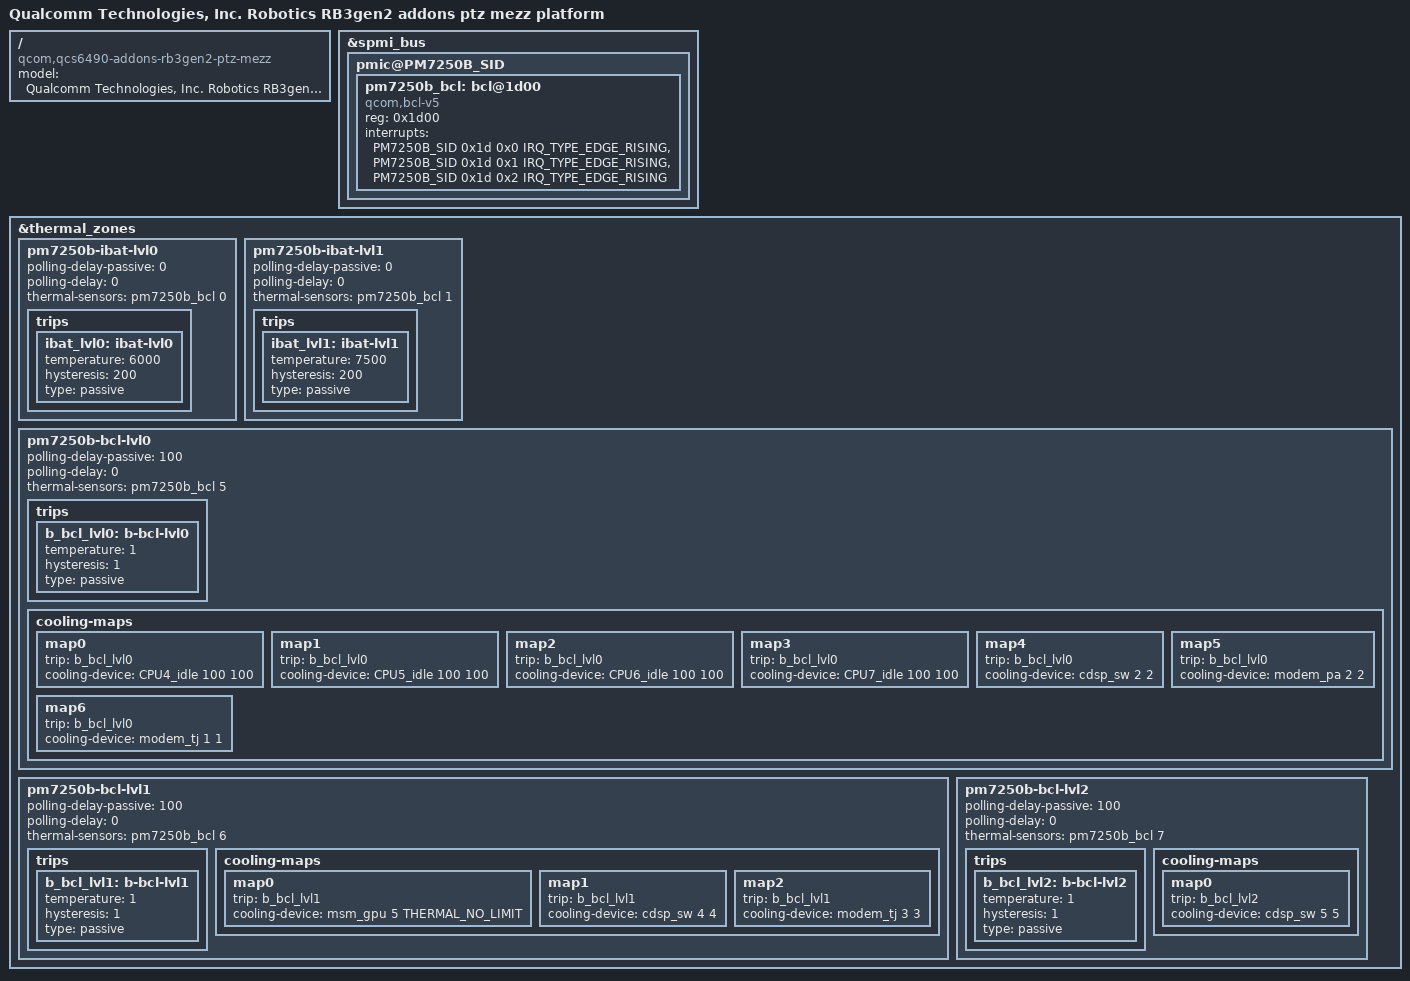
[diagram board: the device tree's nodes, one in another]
// SPDX-License-Identifier: BSD-3-Clause
/*
 * Copyright (c) 2023-2024 Qualcomm Innovation Center, Inc. All rights reserved.
 */

/dts-v1/;

#include "qcs6490-rb3gen2.dts"
#include "qcs6490-addons-rb3gen2.dtsi"

/ {
	model = "Qualcomm Technologies, Inc. Robotics RB3gen2 addons ptz mezz platform";
	compatible = "qcom,qcs6490-addons-rb3gen2-ptz-mezz", "qcom,qcm6490";
};

&spmi_bus {
	pmic@PM7250B_SID {
		pm7250b_bcl: bcl@1d00 {
			compatible = "qcom,bcl-v5";
			reg = <0x1d00>;
			interrupts = <PM7250B_SID 0x1d 0x0 IRQ_TYPE_EDGE_RISING>,
					<PM7250B_SID 0x1d 0x1 IRQ_TYPE_EDGE_RISING>,
					<PM7250B_SID 0x1d 0x2 IRQ_TYPE_EDGE_RISING>;
			interrupt-names = "bcl-lvl0",
						"bcl-lvl1",
						"bcl-lvl2";
			#thermal-sensor-cells = <1>;
		};
	};
};

&thermal_zones {
	pm7250b-ibat-lvl0 {
		polling-delay-passive = <0>;
		polling-delay = <0>;
		thermal-sensors = <&pm7250b_bcl 0>;

		trips {
			ibat_lvl0:ibat-lvl0 {
				temperature = <6000>;
				hysteresis = <200>;
				type = "passive";
			};
		};
	};

	pm7250b-ibat-lvl1 {
		polling-delay-passive = <0>;
		polling-delay = <0>;
		thermal-sensors = <&pm7250b_bcl 1>;

		trips {
			ibat_lvl1:ibat-lvl1 {
				temperature = <7500>;
				hysteresis = <200>;
				type = "passive";
			};
		};
	};

	pm7250b-bcl-lvl0 {
		polling-delay-passive = <100>;
		polling-delay = <0>;
		thermal-sensors = <&pm7250b_bcl 5>;

		trips {
			b_bcl_lvl0: b-bcl-lvl0 {
				temperature = <1>;
				hysteresis = <1>;
				type = "passive";
			};
		};

		cooling-maps {
			map0 {
				trip = <&b_bcl_lvl0>;
				cooling-device = <&CPU4_idle 100 100>;
			};

			map1 {
				trip = <&b_bcl_lvl0>;
				cooling-device = <&CPU5_idle 100 100>;
			};

			map2 {
				trip = <&b_bcl_lvl0>;
				cooling-device = <&CPU6_idle 100 100>;
			};

			map3 {
				trip = <&b_bcl_lvl0>;
				cooling-device = <&CPU7_idle 100 100>;
			};

			map4 {
				trip = <&b_bcl_lvl0>;
				cooling-device = <&cdsp_sw 2 2>;
			};

			map5 {
				trip = <&b_bcl_lvl0>;
				cooling-device = <&modem_pa 2 2>;
			};

			map6 {
				trip = <&b_bcl_lvl0>;
				cooling-device = <&modem_tj 1 1>;
			};
		};
	};

	pm7250b-bcl-lvl1 {
		polling-delay-passive = <100>;
		polling-delay = <0>;
		thermal-sensors = <&pm7250b_bcl 6>;

		trips {
			b_bcl_lvl1: b-bcl-lvl1 {
				temperature = <1>;
				hysteresis = <1>;
				type = "passive";
			};
		};

		cooling-maps {
			map0 {
				trip = <&b_bcl_lvl1>;
				cooling-device = <&msm_gpu 5 THERMAL_NO_LIMIT>;
			};

			map1 {
				trip = <&b_bcl_lvl1>;
				cooling-device = <&cdsp_sw 4 4>;
			};

			map2 {
				trip = <&b_bcl_lvl1>;
				cooling-device = <&modem_tj 3 3>;
			};
		};
	};

	pm7250b-bcl-lvl2 {
		polling-delay-passive = <100>;
		polling-delay = <0>;
		thermal-sensors = <&pm7250b_bcl 7>;

		trips {
			b_bcl_lvl2: b-bcl-lvl2 {
				temperature = <1>;
				hysteresis = <1>;
				type = "passive";
			};
		};

		cooling-maps {
			map0 {
				trip = <&b_bcl_lvl2>;
				cooling-device = <&cdsp_sw 5 5>;
			};
		};
	};
};
